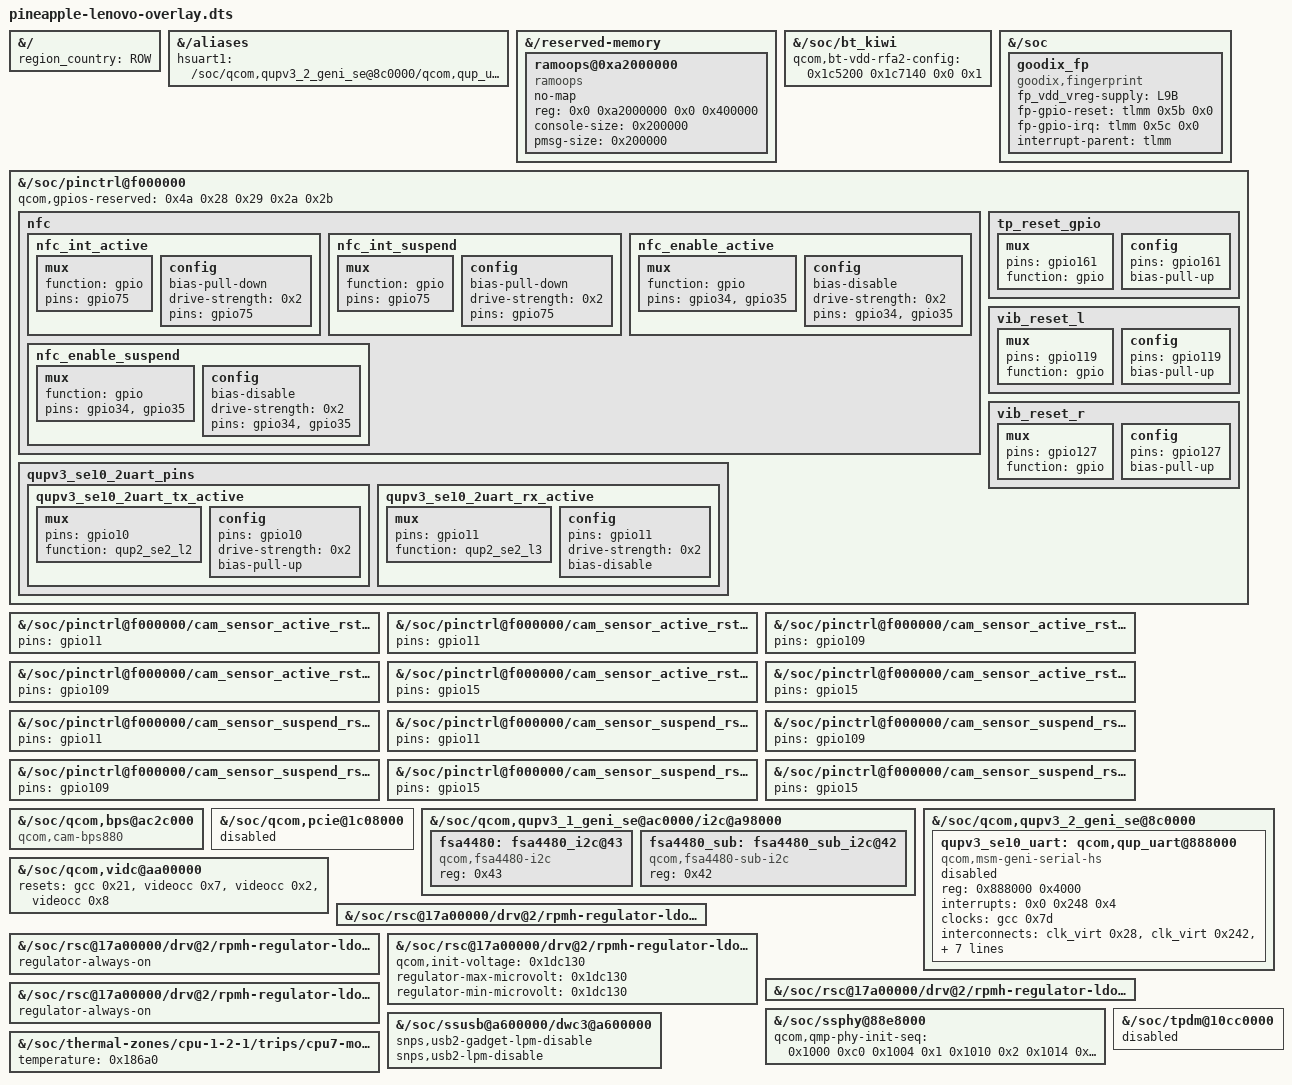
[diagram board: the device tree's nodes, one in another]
// SPDX-License-Identifier: GPL-2.0-only
/*
 * (C) 2026 The LineageOS Project
 *
 * Lenovo changes to the Qualcomm pineapple dtb (stock 18.5.10.037, ROW):
 * region string, ramoops, fingerprint/NFC/uart/vibrator pins, regulators,
 * camera and USB tuning.  Applied last on top of the Qualcomm component
 * overlays.  Properties and nodes that the stock dtb lacks are removed in
 * the qcom/ sources instead (an overlay cannot delete).
 */

/dts-v1/;
/plugin/;

&{/} {
	region_country = "ROW";
};

&{/aliases} {
	hsuart1 = "/soc/qcom,qupv3_2_geni_se@8c0000/qcom,qup_uart@888000";
};

&{/reserved-memory} {
	ramoops@0xa2000000 {
		compatible = "ramoops";
		no-map;
		reg = <0x0 0xa2000000 0x0 0x400000>;
		console-size = <0x200000>;
		pmsg-size = <0x200000>;
	};
};

&{/soc/bt_kiwi} {
	qcom,bt-vdd-rfa2-config = <0x1c5200 0x1c7140 0x0 0x1>;
};

&{/soc} {
	goodix_fp {
		status = "okay";
		fp_vdd_vreg-supply = <&L9B>;
		fp-gpio-reset = <&tlmm 0x5b 0x0>;
		fp-gpio-irq = <&tlmm 0x5c 0x0>;
		interrupt-parent = <&tlmm>;
		compatible = "goodix,fingerprint";
	};
};

&{/soc/pinctrl@f000000} {
	qcom,gpios-reserved = <0x4a 0x28 0x29 0x2a 0x2b>;
};

&{/soc/pinctrl@f000000/cam_sensor_active_rst0/config} {
	pins = "gpio11";
};

&{/soc/pinctrl@f000000/cam_sensor_active_rst0/mux} {
	pins = "gpio11";
};

&{/soc/pinctrl@f000000/cam_sensor_active_rst1/config} {
	pins = "gpio109";
};

&{/soc/pinctrl@f000000/cam_sensor_active_rst1/mux} {
	pins = "gpio109";
};

&{/soc/pinctrl@f000000/cam_sensor_active_rst2/config} {
	pins = "gpio15";
};

&{/soc/pinctrl@f000000/cam_sensor_active_rst2/mux} {
	pins = "gpio15";
};

&{/soc/pinctrl@f000000/cam_sensor_suspend_rst0/config} {
	pins = "gpio11";
};

&{/soc/pinctrl@f000000/cam_sensor_suspend_rst0/mux} {
	pins = "gpio11";
};

&{/soc/pinctrl@f000000/cam_sensor_suspend_rst1/config} {
	pins = "gpio109";
};

&{/soc/pinctrl@f000000/cam_sensor_suspend_rst1/mux} {
	pins = "gpio109";
};

&{/soc/pinctrl@f000000/cam_sensor_suspend_rst2/config} {
	pins = "gpio15";
};

&{/soc/pinctrl@f000000/cam_sensor_suspend_rst2/mux} {
	pins = "gpio15";
};

&{/soc/pinctrl@f000000} {
	nfc {

		nfc_int_active: nfc_int_active {

			mux {
				function = "gpio";
				pins = "gpio75";
			};

			config {
				bias-pull-down;
				drive-strength = <0x2>;
				pins = "gpio75";
			};
		};

		nfc_int_suspend: nfc_int_suspend {

			mux {
				function = "gpio";
				pins = "gpio75";
			};

			config {
				bias-pull-down;
				drive-strength = <0x2>;
				pins = "gpio75";
			};
		};

		nfc_enable_active: nfc_enable_active {

			mux {
				function = "gpio";
				pins = "gpio34", "gpio35";
			};

			config {
				bias-disable;
				drive-strength = <0x2>;
				pins = "gpio34", "gpio35";
			};
		};

		nfc_enable_suspend: nfc_enable_suspend {

			mux {
				function = "gpio";
				pins = "gpio34", "gpio35";
			};

			config {
				bias-disable;
				drive-strength = <0x2>;
				pins = "gpio34", "gpio35";
			};
		};
	};
};

&{/soc/pinctrl@f000000} {
	qupv3_se10_2uart_pins: qupv3_se10_2uart_pins {

		qupv3_se10_2uart_tx_active: qupv3_se10_2uart_tx_active {

			mux {
				pins = "gpio10";
				function = "qup2_se2_l2";
			};

			config {
				pins = "gpio10";
				drive-strength = <0x2>;
				bias-pull-up;
			};
		};

		qupv3_se10_2uart_rx_active: qupv3_se10_2uart_rx_active {

			mux {
				pins = "gpio11";
				function = "qup2_se2_l3";
			};

			config {
				pins = "gpio11";
				drive-strength = <0x2>;
				bias-disable;
			};
		};
	};
};

&{/soc/pinctrl@f000000} {
	tp_reset_gpio: tp_reset_gpio {

		mux {
			pins = "gpio161";
			function = "gpio";
		};

		config {
			pins = "gpio161";
			bias-pull-up;
		};
	};
};

&{/soc/pinctrl@f000000} {
	vib_reset_l: vib_reset_l {

		mux {
			pins = "gpio119";
			function = "gpio";
		};

		config {
			pins = "gpio119";
			bias-pull-up;
		};
	};
};

&{/soc/pinctrl@f000000} {
	vib_reset_r: vib_reset_r {

		mux {
			pins = "gpio127";
			function = "gpio";
		};

		config {
			pins = "gpio127";
			bias-pull-up;
		};
	};
};

&{/soc/qcom,bps@ac2c000} {
	compatible = "qcom,cam-bps880";
};

&{/soc/qcom,pcie@1c08000} {
	status = "disabled";
};

&{/soc/qcom,qupv3_1_geni_se@ac0000/i2c@a98000} {
	fsa4480: fsa4480_i2c@43 {
		compatible = "qcom,fsa4480-i2c";
		reg = <0x43>;
	};
};

&{/soc/qcom,qupv3_1_geni_se@ac0000/i2c@a98000} {
	fsa4480_sub: fsa4480_sub_i2c@42 {
		compatible = "qcom,fsa4480-sub-i2c";
		reg = <0x42>;
	};
};

&{/soc/qcom,qupv3_2_geni_se@8c0000} {
	qupv3_se10_uart: qcom,qup_uart@888000 {
		compatible = "qcom,msm-geni-serial-hs";
		reg = <0x888000 0x4000>;
		reg-names = "se_phys";
		interrupts = <0x0 0x248 0x4>;
		clock-names = "se-clk";
		clocks = <&gcc 0x7d>;
		interconnect-names = "qup-core", "qup-config", "qup-memory";
		interconnects = <&clk_virt 0x28>, <&clk_virt 0x242>, <&gem_noc 0x3>, <&config_noc 0x222>, <&aggre2_noc 0x8>, <&mc_virt 0x200>;
		pinctrl-names = "default", "sleep";
		pinctrl-0 = <&qupv3_se10_2uart_tx_active &qupv3_se10_2uart_rx_active>;
		pinctrl-1 = <&qupv3_se10_2uart_tx_active &qupv3_se10_2uart_rx_active>;
		qcom,auto-suspend-disable;
		status = "disabled";
	};
};

&{/soc/qcom,vidc@aa00000} {
	reset-names = "video_axi_reset", "video_xo_reset", "video_mvs0c_reset", "video_mvs0_reset";
	resets = <&gcc 0x21>, <&videocc 0x7>, <&videocc 0x2>, <&videocc 0x8>;
};

&{/soc/rsc@17a00000/drv@2/rpmh-regulator-ldob1} {
	status = "ok";
};

&{/soc/rsc@17a00000/drv@2/rpmh-regulator-ldob1/regulator-pm-humu-l1} {
	regulator-always-on;
	status = "ok";
};

&{/soc/rsc@17a00000/drv@2/rpmh-regulator-ldob12/regulator-pm-humu-l12} {
	qcom,init-voltage = <0x1dc130>;
	regulator-max-microvolt = <0x1dc130>;
	regulator-min-microvolt = <0x1dc130>;
};

&{/soc/rsc@17a00000/drv@2/rpmh-regulator-ldob14} {
	status = "ok";
};

&{/soc/rsc@17a00000/drv@2/rpmh-regulator-ldob14/regulator-pm-humu-l14} {
	regulator-always-on;
	status = "ok";
};

&{/soc/ssphy@88e8000} {
	qcom,qmp-phy-init-seq = <0x1000 0xc0 0x1004 0x1 0x1010 0x2 0x1014 0x16 0x1018 0x36 0x101c 0x4 0x1020 0x16 0x1024 0x41 0x1028 0x41 0x102c 0x0 0x1030 0x55 0x1034 0x75 0x1038 0x1 0x103c 0x1 0x1048 0x25 0x104c 0x2 0x1050 0x5c 0x1054 0xf 0x1058 0x5c 0x105c 0xf 0x1060 0xc0 0x1064 0x1 0x1070 0x2 0x1074 0x16 0x1078 0x36 0x1080 0x8 0x1084 0x1a 0x1088 0x41 0x108c 0x0 0x1090 0x55 0x1094 0x75 0x1098 0x1 0x10a8 0x25 0x10ac 0x2 0x10bc 0xa 0x10c0 0x1 0x10cc 0x62 0x10d0 0x2 0x10e8 0xc 0x1110 0x1a 0x1124 0x14 0x1140 0x4 0x1170 0x20 0x1174 0x16 0x11a4 0xb6 0x11a8 0x4b 0x11ac 0x37 0x11b4 0xc 0x1234 0x0 0x1238 0x0 0x123c 0x1f 0x1240 0x9 0x1284 0xf5 0x128c 0x3f 0x1290 0x3f 0x1294 0x5f 0x12a4 0x12 0x12e4 0x21 0x1408 0xa 0x1414 0x6 0x1430 0x2f 0x1434 0x7f 0x143c 0xff 0x1440 0xf 0x1444 0x99 0x144c 0x8 0x1450 0x8 0x1454 0x0 0x1458 0xa 0x1460 0xa0 0x14d4 0x54 0x14d8 0xf 0x14dc 0x13 0x14ec 0xf 0x14f0 0x4a 0x14f4 0xa 0x14f8 0x7 0x14fc 0x0 0x1510 0x47 0x151c 0x4 0x1524 0xe 0x155c 0x3f 0x1560 0xbf 0x1564 0xff 0x1568 0xdf 0x156c 0xed 0x1570 0xdc 0x1574 0x5c 0x1578 0x9f 0x157c 0x1d 0x1580 0x3d 0x15a0 0x4 0x15a4 0x38 0x15a8 0xc 0x15b0 0x10 0x15e4 0x14 0x15f8 0x8 0x1634 0x0 0x1638 0x0 0x163c 0x1f 0x1640 0x9 0x1684 0xf5 0x168c 0x3f 0x1690 0x3f 0x1694 0x5f 0x16a4 0x12 0x16e4 0x5 0x1808 0xa 0x1814 0x6 0x1830 0x2f 0x1834 0x7f 0x183c 0xff 0x1840 0xf 0x1844 0x99 0x184c 0x8 0x1850 0x8 0x1854 0x0 0x1858 0xa 0x1860 0xa0 0x18d4 0x54 0x18d8 0xf 0x18dc 0x13 0x18ec 0xf 0x18f0 0x4a 0x18f4 0xa 0x18f8 0x7 0x18fc 0x0 0x1910 0x47 0x191c 0x4 0x1924 0xe 0x195c 0xbf 0x1960 0xbf 0x1964 0xbf 0x1968 0xdf 0x196c 0xfd 0x1970 0xdc 0x1974 0x5c 0x1978 0x9f 0x197c 0x1d 0x1980 0x3d 0x19a0 0x4 0x19a4 0x38 0x19a8 0xc 0x19b0 0x10 0x19e4 0x14 0x19f8 0x8 0x1cc4 0xc4 0x1cc8 0x89 0x1ccc 0x20 0x1cd8 0x13 0x1cdc 0x21 0x1d88 0x99 0x1d90 0xe7 0x1d94 0x3 0x1db0 0xa 0x1dc0 0x88 0x1dc4 0x13 0x1dd0 0xc 0x1ddc 0x4b 0x1dec 0x10 0x1f00 0x68 0x1f18 0xf8 0x1f3c 0x7 0x1f40 0x40 0x1f44 0x0 0x120c 0x30 0x160c 0x30>;
};

&{/soc/ssusb@a600000/dwc3@a600000} {
	snps,usb2-gadget-lpm-disable;
	snps,usb2-lpm-disable;
};

&{/soc/thermal-zones/cpu-1-2-1/trips/cpu7-mon-trip} {
	temperature = <0x186a0>;
};

&{/soc/tpdm@10cc0000} {
	status = "disabled";
};

